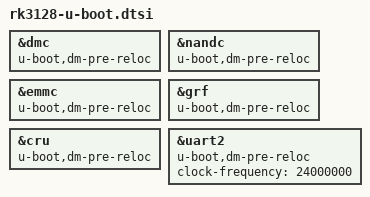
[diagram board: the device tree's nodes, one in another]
/*
 * (C) Copyright 2018 Rockchip Electronics Co., Ltd
 *
 * SPDX-License-Identifier:     GPL-2.0+
 */


&dmc {
	u-boot,dm-pre-reloc;
};

&nandc {
	u-boot,dm-pre-reloc;
	status = "okay";
};

&emmc {
	u-boot,dm-pre-reloc;
	status = "okay";
};

&grf {
	u-boot,dm-pre-reloc;
};

&cru {
	u-boot,dm-pre-reloc;
};

&uart2 {
	u-boot,dm-pre-reloc;
	clock-frequency = <24000000>;
};
